# f29h85x_input_xbar_regs register map
Vendor: Texas Instruments
Peripheral module from a debugger description file (folder HSM).
Registers are 32-bit, read-write, no defined reset value unless marked. A register's access mark holds for its fields unless they carry their own. Offsets are as the file gives them; lines under a group give offsets from that group; [hi:lo] are bit positions; {n}, {i} and the like mark numbered series; 'fields as' and 'values as' point back to an identical list; <NAME> marks a mode.

## INPUT_XBAR_REGS — INPUT XBAR Registers
{0x0+4i} INPUTSELECT[{i}] (i=0..63) — Input Select Register (GPIO0 to x)
  [15:0] SELECT — Select GPIO for INPUT{#} signal
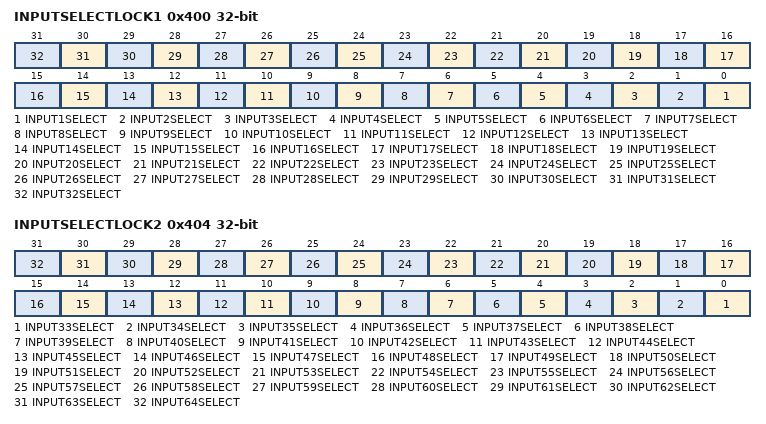
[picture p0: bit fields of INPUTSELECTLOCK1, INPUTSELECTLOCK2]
0x400 INPUTSELECTLOCK1 — Input Select Lock Register 1
  [n-1] INPUT{n}SELECT (n=1..32) — Lock bit for INPUT{n}SELECT Register
0x404 INPUTSELECTLOCK2 — Input Select Lock Register 2
  [n-33] INPUT{n}SELECT (n=33..64) — Lock bit for INPUT{n}SELECT Register
